# LargeDummyDevice register map
File version: 1.0
Registers are 32-bit, read-write, no defined reset value unless marked. A register's access mark holds for its fields unless they carry their own. Offsets are from the block's base; [hi:lo] are bit positions.

## PERIPHERAL_46
Base 0x4002D000
0x04 REG_1 — Register 1
  [30] FIELD_13, [33:29] FIELD_6, [26] FIELD_15, [27:25] FIELD_20, [23] FIELD_1, [24:23] FIELD_21, [20] FIELD_5, [22:20] FIELD_28, [20:19] FIELD_11, [18] FIELD_14, [18] FIELD_17, [18] FIELD_24, [21:17] FIELD_7, [19:15] FIELD_3, [16:14] FIELD_4, [14] FIELD_19, [15:14] FIELD_26, [17:14] FIELD_27, [16:12] FIELD_22, [15:11] FIELD_8, [10] FIELD_23, [9] FIELD_12, [10:8] FIELD_16, [9:7] FIELD_9, [9:7] FIELD_10, [6:3] FIELD_2, [3:2] FIELD_25, [3:0] FIELD_18
0x08 REG_2 — Register 2
  [34:31] FIELD_10, [30] FIELD_3, [30:29] FIELD_8, [33:29] FIELD_17, [29] FIELD_18, [31:29] FIELD_19, [32:28] FIELD_7, [30:26] FIELD_16, [25:24] FIELD_15, [24:21] FIELD_5, [25:21] FIELD_14, [16] FIELD_4, [10:8] FIELD_13, [9:7] FIELD_2, [6] FIELD_12, [7:5] FIELD_6, [9:5] FIELD_9, [2:1] FIELD_1, [1] FIELD_11
0x0C REG_3 — Register 3
  [34:31] FIELD_31, [31:29] FIELD_4, [30:29] FIELD_10, [32:28] FIELD_13, [30:28] FIELD_32, [26:24] FIELD_27, [24] FIELD_29, [24:22] FIELD_1, [22] FIELD_15, [23:21] FIELD_17, [21] FIELD_18, [24:20] FIELD_11, [23:19] FIELD_2, [23:19] FIELD_3, [22:19] FIELD_14, [21:17] FIELD_23, [18:16] FIELD_28, [16:15] FIELD_30, [17:14] FIELD_21, [17:13] FIELD_19, [16:12] FIELD_5, [12:10] FIELD_20, [11:10] FIELD_25, [12:8] FIELD_8, [9:7] FIELD_24, [7:5] FIELD_7, [9:5] FIELD_22, [6:4] FIELD_9, [5:3] FIELD_12, [7:3] FIELD_26, [1:0] FIELD_6, [1:0] FIELD_16
0x10 REG_4 — Register 4
  [12] FIELD_2, [12] FIELD_3, [12:10] FIELD_1
0x14 REG_5 — Register 5
  [24:21] FIELD_9, [22:19] FIELD_4, [19] FIELD_7, [20:17] FIELD_5, [15] FIELD_3, [16:12] FIELD_1, [7] FIELD_2, [8:5] FIELD_10, [4:1] FIELD_6, [1] FIELD_11, [3:0] FIELD_8
0x18 REG_6 — Register 6
  [31:30] FIELD_1, [32:28] FIELD_2, [32:28] FIELD_11, [25:23] FIELD_12, [23:22] FIELD_4, [19:15] FIELD_8, [14] FIELD_10, [17:13] FIELD_3, [14:10] FIELD_5, [14:10] FIELD_7, [10:7] FIELD_9, [2] FIELD_6, [4:2] FIELD_13
0x1C REG_7 — Register 7
  [31] FIELD_9, [29:28] FIELD_6, [29:25] FIELD_7, [25] FIELD_8, [22:19] FIELD_4, [18:14] FIELD_1, [9:8] FIELD_2, [11:8] FIELD_5, [5:1] FIELD_3
0x20 REG_8 — Register 8
  [28:27] FIELD_16, [28:26] FIELD_22, [28:25] FIELD_11, [27:23] FIELD_12, [23:20] FIELD_3, [24:20] FIELD_18, [24:20] FIELD_23, [22:20] FIELD_24, [23:19] FIELD_17, [19] FIELD_26, [22:19] FIELD_27, [19:17] FIELD_2, [21:17] FIELD_9, [17:16] FIELD_8, [18:14] FIELD_5, [18:14] FIELD_14, [15:12] FIELD_20, [14:10] FIELD_10, [10:6] FIELD_4, [8:6] FIELD_13, [8:6] FIELD_25, [8:4] FIELD_7, [4] FIELD_19, [5:4] FIELD_28, [3:1] FIELD_1, [4:1] FIELD_15, [3:0] FIELD_6, [1:0] FIELD_21
0x24 REG_9 — Register 9
  [31:30] FIELD_24, [30:28] FIELD_18, [27:26] FIELD_26, [27:23] FIELD_1, [23] FIELD_30, [26:22] FIELD_11, [25:22] FIELD_27, [24:21] FIELD_9, [25:21] FIELD_12, [22:19] FIELD_7, [23:19] FIELD_22, [20:19] FIELD_29, [19:18] FIELD_25, [22:18] FIELD_32, [19:17] FIELD_4, [20:17] FIELD_14, [20:17] FIELD_16, [18:16] FIELD_28, [14:13] FIELD_2, [13] FIELD_3, [17:13] FIELD_13, [13:11] FIELD_5, [13:11] FIELD_20, [11:9] FIELD_19, [6] FIELD_10, [6] FIELD_17, [3:2] FIELD_8, [3:1] FIELD_6, [3:1] FIELD_15, [3:1] FIELD_23, [2:0] FIELD_21, [0] FIELD_31
0x28 REG_10 — Register 10
  [33:31] FIELD_15, [30:29] FIELD_3, [31:28] FIELD_6, [32:28] FIELD_8, [30:27] FIELD_20, [29:25] FIELD_7, [25] FIELD_25, [27:23] FIELD_1, [24:23] FIELD_22, [21] FIELD_12, [22:21] FIELD_17, [24:20] FIELD_14, [22:19] FIELD_18, [19:17] FIELD_26, [14:13] FIELD_2, [15:13] FIELD_21, [12] FIELD_10, [15:12] FIELD_16, [11:8] FIELD_24, [7] FIELD_9, [10:7] FIELD_13, [8:6] FIELD_5, [9:5] FIELD_4, [7:4] FIELD_11, [6:4] FIELD_19, [4] FIELD_23
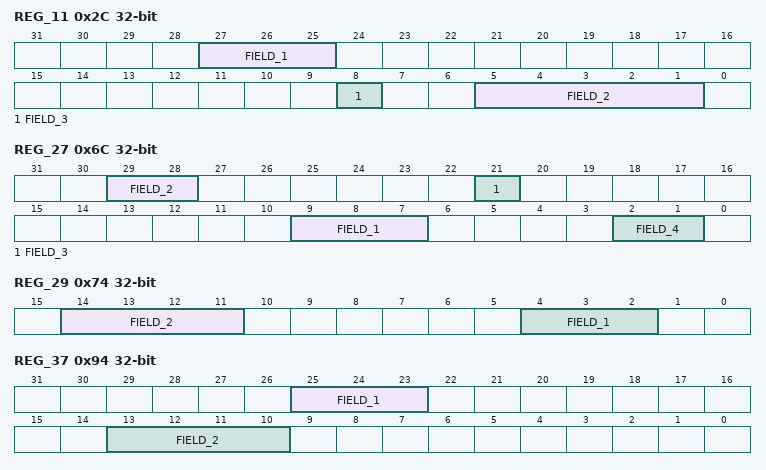
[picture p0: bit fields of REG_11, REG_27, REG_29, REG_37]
0x2C REG_11 — Register 11
  [27:25] FIELD_1, [8] FIELD_3, [5:1] FIELD_2
0x30 REG_12 — Register 12
  [33:31] FIELD_6, [33:31] FIELD_14, [29:27] FIELD_12, [28:27] FIELD_17, [29:26] FIELD_1, [27:26] FIELD_3, [26:25] FIELD_7, [27:24] FIELD_16, [18] FIELD_10, [19:15] FIELD_5, [15] FIELD_13, [14:13] FIELD_19, [12:9] FIELD_18, [9:8] FIELD_4, [7:6] FIELD_15, [7:5] FIELD_2, [6:5] FIELD_8, [2:0] FIELD_9, [0] FIELD_11
0x34 REG_13 — Register 13
  [35:31] FIELD_3, [25:24] FIELD_7, [18:14] FIELD_1, [17:14] FIELD_4, [12:11] FIELD_2, [10] FIELD_5, [4] FIELD_6
0x38 REG_14 — Register 14
  [33:30] FIELD_18, [29] FIELD_14, [28] FIELD_10, [31:28] FIELD_12, [29:27] FIELD_5, [28:27] FIELD_6, [28:26] FIELD_3, [28:26] FIELD_15, [28:24] FIELD_13, [23:22] FIELD_8, [16] FIELD_4, [18:15] FIELD_17, [15:14] FIELD_1, [12:10] FIELD_9, [7:6] FIELD_2, [5:2] FIELD_11, [6:2] FIELD_16, [0] FIELD_7
0x3C REG_15 — Register 15
  [34:30] FIELD_9, [28:27] FIELD_3, [26] FIELD_2, [27:25] FIELD_17, [25:23] FIELD_10, [22] FIELD_1, [26:22] FIELD_12, [22:21] FIELD_6, [24:21] FIELD_25, [23:20] FIELD_7, [20:19] FIELD_16, [19:18] FIELD_8, [19:18] FIELD_18, [17:14] FIELD_14, [13] FIELD_19, [15:12] FIELD_21, [10] FIELD_27, [12:9] FIELD_4, [10:9] FIELD_20, [11:9] FIELD_23, [9:8] FIELD_22, [6] FIELD_5, [10:6] FIELD_15, [6:3] FIELD_24, [4:3] FIELD_26, [2] FIELD_11, [1] FIELD_13
0x40 REG_16 — Register 16
  [32:31] FIELD_13, [32:29] FIELD_1, [32:29] FIELD_17, [31:27] FIELD_22, [26:25] FIELD_7, [21:20] FIELD_19, [17] FIELD_11, [20:16] FIELD_21, [16:15] FIELD_10, [16:14] FIELD_8, [16:12] FIELD_6, [14:11] FIELD_3, [11] FIELD_16, [13:10] FIELD_12, [11:8] FIELD_4, [12:8] FIELD_15, [8] FIELD_18, [6:5] FIELD_5, [6:3] FIELD_2, [5:3] FIELD_20, [4:2] FIELD_9, [2:0] FIELD_14
0x44 REG_17 — Register 17
  [30] FIELD_1, [28] FIELD_2, [28:26] FIELD_9, [25] FIELD_7, [28:25] FIELD_8, [16:15] FIELD_5, [18:14] FIELD_4, [14:13] FIELD_6, [11] FIELD_3
0x48 REG_18 — Register 18
  [33:31] FIELD_13, [33:30] FIELD_12, [30] FIELD_23, [33:29] FIELD_4, [30:29] FIELD_17, [30:29] FIELD_26, [29] FIELD_29, [29:28] FIELD_7, [25] FIELD_21, [27:24] FIELD_16, [24] FIELD_27, [24:21] FIELD_8, [23:21] FIELD_14, [21:20] FIELD_3, [22:20] FIELD_22, [23:19] FIELD_2, [18:17] FIELD_20, [19:17] FIELD_31, [17:15] FIELD_6, [15] FIELD_28, [18:14] FIELD_10, [16:14] FIELD_18, [13:11] FIELD_5, [11] FIELD_9, [15:11] FIELD_24, [8:7] FIELD_30, [7:6] FIELD_1, [8:5] FIELD_25, [3:1] FIELD_15, [3:0] FIELD_11, [0] FIELD_19
0x4C REG_19 — Register 19
  [31:30] FIELD_8, [33:29] FIELD_4, [28] FIELD_23, [29:26] FIELD_1, [26:25] FIELD_24, [25:22] FIELD_5, [25:22] FIELD_14, [25:22] FIELD_17, [24:22] FIELD_19, [21:20] FIELD_26, [21:20] FIELD_29, [22:18] FIELD_3, [19:18] FIELD_21, [18:17] FIELD_13, [18:16] FIELD_11, [18:14] FIELD_22, [13] FIELD_12, [12:11] FIELD_20, [9] FIELD_25, [8:7] FIELD_15, [4] FIELD_10, [3] FIELD_2, [3:2] FIELD_6, [4:2] FIELD_16, [3:2] FIELD_18, [2:1] FIELD_27, [4:1] FIELD_28, [0] FIELD_7, [1:0] FIELD_9
0x50 REG_20 — Register 20
  [34:30] FIELD_8, [30:29] FIELD_10, [25:22] FIELD_7, [21] FIELD_9, [16:15] FIELD_6, [8:7] FIELD_5, [6:5] FIELD_3, [6:5] FIELD_4, [7:4] FIELD_2, [5:1] FIELD_1
0x54 REG_21 — Register 21
  [34:31] FIELD_3, [31:30] FIELD_1, [32:29] FIELD_5, [32:28] FIELD_8, [31:28] FIELD_10, [28:25] FIELD_11, [22:20] FIELD_2, [21:19] FIELD_4, [19:16] FIELD_6, [16:13] FIELD_12, [10] FIELD_9, [8:6] FIELD_13, [7:6] FIELD_14, [2] FIELD_7
0x58 REG_22 — Register 22
  [32:30] FIELD_15, [34:30] FIELD_19, [29] FIELD_3, [31:29] FIELD_12, [30:29] FIELD_16, [28:25] FIELD_8, [28:24] FIELD_20, [25:24] FIELD_22, [24:23] FIELD_21, [24:21] FIELD_5, [23:19] FIELD_18, [18:17] FIELD_17, [15] FIELD_1, [18:14] FIELD_2, [14] FIELD_7, [16:14] FIELD_11, [9] FIELD_6, [12:9] FIELD_9, [8:6] FIELD_4, [8:6] FIELD_14, [5:3] FIELD_10, [1] FIELD_13
0x5C REG_23 — Register 23
  [31] FIELD_7, [33:31] FIELD_9, [33:30] FIELD_3, [31:28] FIELD_2, [28:27] FIELD_5, [24:21] FIELD_10, [23:21] FIELD_11, [20:19] FIELD_8, [14] FIELD_4, [11] FIELD_6, [10:8] FIELD_12, [6:3] FIELD_1
0x60 REG_24 — Register 24
  [31:30] FIELD_10, [28:25] FIELD_7, [23] FIELD_2, [25:22] FIELD_9, [26:22] FIELD_12, [24:20] FIELD_6, [16:15] FIELD_11, [16:14] FIELD_8, [15:12] FIELD_5, [12:8] FIELD_4, [6] FIELD_13, [7:5] FIELD_1, [3] FIELD_3
0x64 REG_25 — Register 25
  [18] FIELD_1
0x68 REG_26 — Register 26
  [35:31] FIELD_3, [31:30] FIELD_1, [31:28] FIELD_2, [29:27] FIELD_5, [23] FIELD_10, [25:22] FIELD_13, [16:15] FIELD_9, [17:13] FIELD_8, [14:11] FIELD_11, [9:6] FIELD_12, [6:5] FIELD_7, [4] FIELD_6, [2:1] FIELD_4
0x6C REG_27 — Register 27
  [29:28] FIELD_2, [21] FIELD_3, [9:7] FIELD_1, [2:1] FIELD_4
0x70 REG_28 — Register 28
  [30:29] FIELD_4, [31:29] FIELD_5, [28] FIELD_8, [25:24] FIELD_6, [25:22] FIELD_7, [21:20] FIELD_9, [23:20] FIELD_11, [19:18] FIELD_2, [18] FIELD_3, [17:14] FIELD_1, [11:7] FIELD_13, [5:3] FIELD_12, [3:2] FIELD_14, [0] FIELD_10
0x74 REG_29 — Register 29
  [14:11] FIELD_2, [4:2] FIELD_1
0x78 REG_30 — Register 30
  [19] FIELD_1
0x7C REG_31 — Register 31
  [31:30] FIELD_4, [24:23] FIELD_12, [23:21] FIELD_10, [20:19] FIELD_1, [21:18] FIELD_2, [16:15] FIELD_5, [18:15] FIELD_6, [8:7] FIELD_7, [10:7] FIELD_11, [5] FIELD_3, [5:2] FIELD_9, [2:1] FIELD_8
0x80 REG_32 — Register 32
  [32:31] FIELD_10, [32:30] FIELD_1, [29] FIELD_7, [32:29] FIELD_25, [29:25] FIELD_11, [27:24] FIELD_23, [22] FIELD_20, [25:21] FIELD_5, [19:17] FIELD_3, [20:17] FIELD_26, [20:16] FIELD_6, [16] FIELD_14, [20:16] FIELD_28, [15] FIELD_29, [16:14] FIELD_22, [13] FIELD_30, [15:12] FIELD_27, [11:10] FIELD_12, [11:10] FIELD_19, [12:9] FIELD_13, [11:7] FIELD_2, [6] FIELD_4, [9:6] FIELD_31, [4] FIELD_17, [4:3] FIELD_9, [7:3] FIELD_15, [3:1] FIELD_16, [1] FIELD_18, [1:0] FIELD_8, [4:0] FIELD_21, [3:0] FIELD_24
0x84 REG_33 — Register 33
  [31:29] FIELD_5, [26:25] FIELD_2, [24] FIELD_3, [21] FIELD_6, [16:15] FIELD_1, [7:6] FIELD_7, [7:4] FIELD_4, [5:3] FIELD_9, [6:2] FIELD_8
0x88 REG_34 — Register 34
  [30] FIELD_5, [32:30] FIELD_29, [32:28] FIELD_19, [32:28] FIELD_26, [28:27] FIELD_17, [29:27] FIELD_20, [29:25] FIELD_10, [28:25] FIELD_21, [25:23] FIELD_27, [26:22] FIELD_24, [21] FIELD_3, [22:19] FIELD_23, [16] FIELD_7, [19:15] FIELD_15, [18:14] FIELD_18, [14:13] FIELD_13, [13] FIELD_25, [14:12] FIELD_12, [13:9] FIELD_28, [11:9] FIELD_30, [8] FIELD_4, [9:8] FIELD_9, [7] FIELD_8, [8:7] FIELD_14, [7:6] FIELD_22, [6:4] FIELD_6, [3] FIELD_11, [5:2] FIELD_2, [2] FIELD_16, [1] FIELD_1
0x8C REG_35 — Register 35
  [30] FIELD_26, [33:29] FIELD_7, [30:29] FIELD_24, [30:28] FIELD_13, [28] FIELD_14, [26:25] FIELD_4, [28:24] FIELD_22, [23:19] FIELD_28, [22:18] FIELD_17, [16] FIELD_8, [20:16] FIELD_23, [15] FIELD_3, [19:15] FIELD_21, [16:14] FIELD_10, [17:13] FIELD_12, [14:13] FIELD_15, [16:12] FIELD_27, [11] FIELD_9, [14:10] FIELD_25, [11:9] FIELD_5, [11:9] FIELD_18, [9:5] FIELD_1, [5:2] FIELD_11, [3:2] FIELD_16, [2:0] FIELD_2, [1:0] FIELD_6, [2:0] FIELD_19, [4:0] FIELD_20
0x90 REG_36 — Register 36
  [33:31] FIELD_1, [35:31] FIELD_4, [31:27] FIELD_19, [26] FIELD_11, [19:16] FIELD_18, [17:15] FIELD_2, [16:14] FIELD_5, [17:14] FIELD_15, [17:13] FIELD_3, [13:12] FIELD_14, [11:10] FIELD_9, [9] FIELD_16, [12:8] FIELD_7, [10:7] FIELD_8, [11:7] FIELD_13, [11:7] FIELD_17, [7:4] FIELD_10, [5:2] FIELD_20, [3:1] FIELD_6, [5:1] FIELD_12
0x94 REG_37 — Register 37
  [25:23] FIELD_1, [13:10] FIELD_2
0x98 REG_38 — Register 38
  [26] FIELD_1, [29:25] FIELD_2, [27:23] FIELD_3
0x9C REG_39 — Register 39
  [34:31] FIELD_15, [34:30] FIELD_11, [32:29] FIELD_20, [28:27] FIELD_5, [29:27] FIELD_6, [25] FIELD_4, [25] FIELD_22, [23] FIELD_8, [27:23] FIELD_12, [24:22] FIELD_25, [20] FIELD_26, [22:20] FIELD_28, [18:17] FIELD_21, [20:16] FIELD_2, [17:16] FIELD_13, [16:15] FIELD_1, [14] FIELD_9, [15:14] FIELD_18, [14:13] FIELD_23, [13:11] FIELD_16, [7:6] FIELD_19, [7:4] FIELD_24, [7:3] FIELD_7, [7:3] FIELD_17, [4:2] FIELD_14, [1] FIELD_3, [2:0] FIELD_10, [1:0] FIELD_27
0xA0 REG_40 — Register 40
  [35:31] FIELD_3, [31] FIELD_5, [31:28] FIELD_6, [26:25] FIELD_4, [21:18] FIELD_8, [15] FIELD_2, [7:6] FIELD_1, [4] FIELD_7
0xA4 REG_41 — Register 41
  [32:31] FIELD_4, [32:28] FIELD_13, [30:27] FIELD_1, [29:26] FIELD_7, [25] FIELD_9, [24:23] FIELD_8, [26:22] FIELD_3, [24:20] FIELD_6, [20:19] FIELD_14, [20:18] FIELD_10, [10] FIELD_12, [10:8] FIELD_5, [10:7] FIELD_2, [3:0] FIELD_11
0xA8 REG_42 — Register 42
  [29] FIELD_5, [33:29] FIELD_10, [28:25] FIELD_2, [22:21] FIELD_11, [21] FIELD_16, [24:20] FIELD_13, [21:17] FIELD_3, [17:16] FIELD_6, [19:15] FIELD_19, [17:14] FIELD_1, [18:14] FIELD_18, [14:13] FIELD_7, [10:8] FIELD_15, [9:7] FIELD_17, [6] FIELD_9, [5] FIELD_4, [3:2] FIELD_8, [1] FIELD_14, [3:0] FIELD_12
0xAC REG_43 — Register 43
  [32:31] FIELD_2, [34:31] FIELD_10, [35:31] FIELD_12, [32:31] FIELD_19, [34:30] FIELD_4, [28] FIELD_6, [26:25] FIELD_13, [27:23] FIELD_5, [23:21] FIELD_11, [22:19] FIELD_3, [20:19] FIELD_17, [18] FIELD_16, [16] FIELD_9, [15] FIELD_1, [10:9] FIELD_7, [12:9] FIELD_18, [6:3] FIELD_8, [3:2] FIELD_14, [4:0] FIELD_15
0xB0 REG_44 — Register 44
  [31:30] FIELD_12, [30:28] FIELD_6, [31:28] FIELD_14, [26] FIELD_27, [26:24] FIELD_3, [24:23] FIELD_7, [24:20] FIELD_19, [19:17] FIELD_16, [16] FIELD_8, [16] FIELD_9, [19:16] FIELD_20, [16:15] FIELD_5, [17:15] FIELD_23, [14] FIELD_10, [15:13] FIELD_13, [14:12] FIELD_26, [13:11] FIELD_2, [12:10] FIELD_11, [14:10] FIELD_21, [11:7] FIELD_15, [11:7] FIELD_24, [8:6] FIELD_25, [7:5] FIELD_4, [8:4] FIELD_1, [6:4] FIELD_22, [3] FIELD_18, [3:2] FIELD_17
0xB4 REG_45 — Register 45
  [34:30] FIELD_2, [33:30] FIELD_18, [31:30] FIELD_23, [29:28] FIELD_9, [28:27] FIELD_6, [30:27] FIELD_10, [23] FIELD_13, [27:23] FIELD_14, [26:22] FIELD_5, [23:21] FIELD_4, [25:21] FIELD_21, [21:19] FIELD_1, [19:17] FIELD_8, [20:17] FIELD_11, [18:17] FIELD_12, [19:15] FIELD_3, [16:15] FIELD_16, [15:11] FIELD_17, [10] FIELD_7, [10:7] FIELD_20, [3] FIELD_15, [3] FIELD_22, [3:2] FIELD_19
0xB8 REG_46 — Register 46
  [31] FIELD_12, [32:31] FIELD_14, [29:26] FIELD_10, [22:20] FIELD_6, [15] FIELD_7, [16:14] FIELD_11, [17:13] FIELD_1, [15:12] FIELD_2, [14:12] FIELD_9, [13:10] FIELD_4, [10] FIELD_13, [9] FIELD_8, [4] FIELD_3, [5:2] FIELD_5
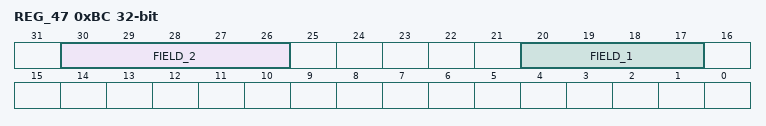
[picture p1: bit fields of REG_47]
0xBC REG_47 — Register 47
  [30:26] FIELD_2, [20:17] FIELD_1
